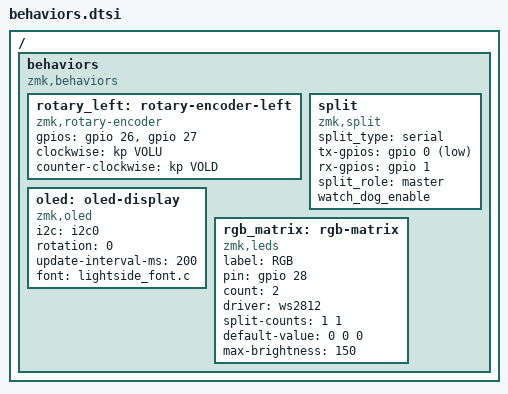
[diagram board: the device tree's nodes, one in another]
/ {
    behaviors {
        compatible = "zmk,behaviors";

        // Энкодер
        rotary_left: rotary-encoder-left {
            compatible = "zmk,rotary-encoder";
            gpios = <&gpio 26 0>, <&gpio 27 0>; // GP26 = B, GP27 = A
            clockwise = <&kp VOLU>;
            counter-clockwise = <&kp VOLD>;
        };

        // Split protocol
        split: split {
            compatible = "zmk,split";
            split_type = "serial";
            tx-gpios = <&gpio 0 1>;   // GP0 TX
            rx-gpios = <&gpio 1 0>;   // GP1 RX
            split_role = "master";
            watch_dog_enable;
        };

        // OLED
        oled: oled-display {
            compatible = "zmk,oled";
            i2c = <&i2c0>;
            rotation = <0>;
            update-interval-ms = <200>;
            font = "lightside_font.c";
        };

        // RGB / WS2812
        rgb_matrix: rgb-matrix {
            compatible = "zmk,leds";
            label = "RGB";
            pin = <&gpio 28>;
            count = <2>;
            driver = "ws2812";
            split-counts = <1 1>; // LED split: master=1, slave=1
            default-value = <0 0 0>;
            max-brightness = <150>;
        };
    };
};

